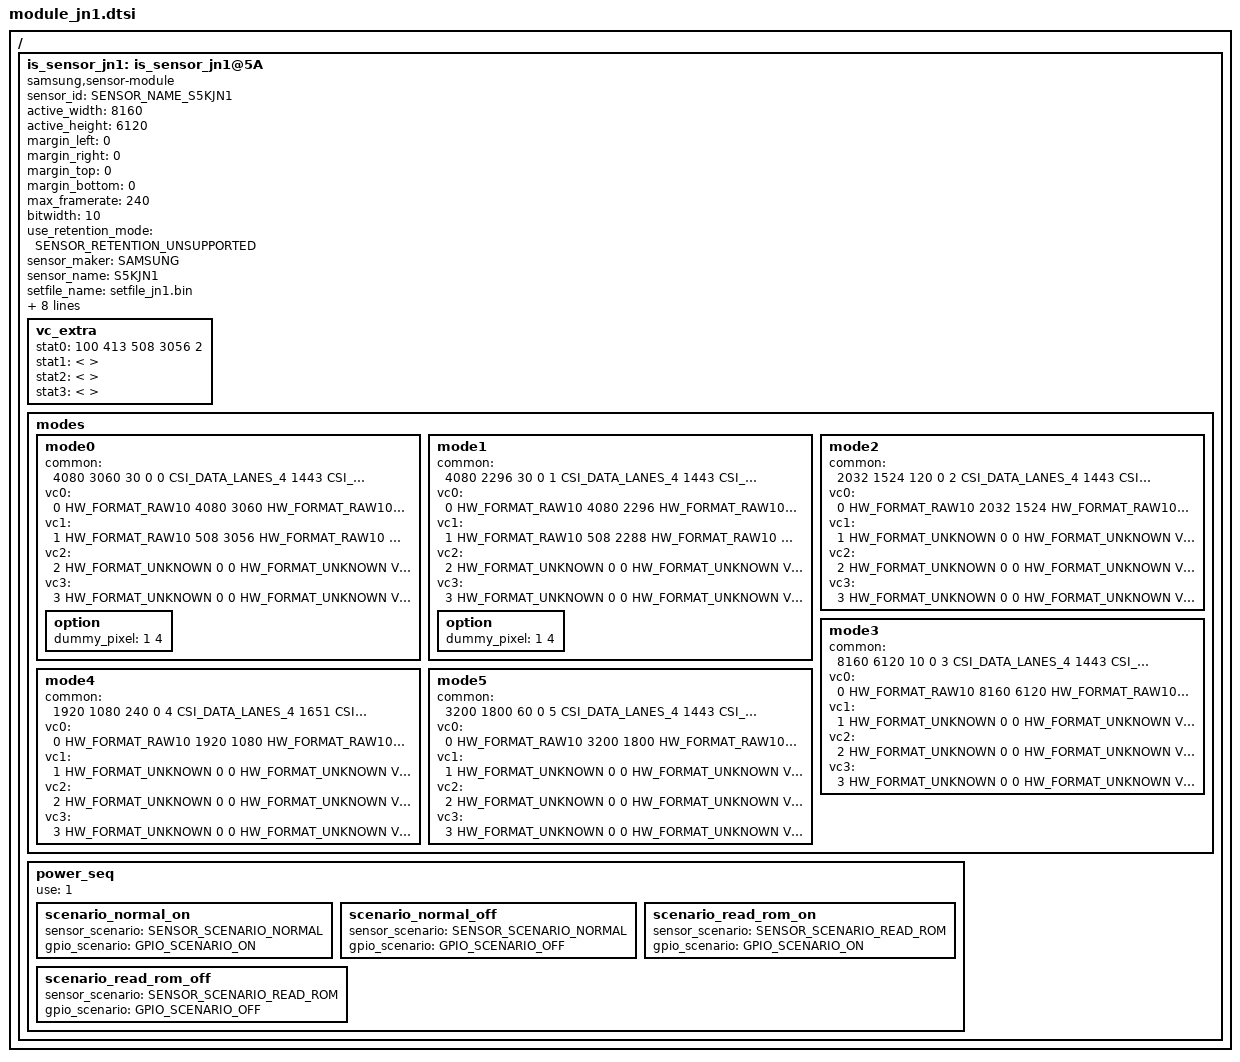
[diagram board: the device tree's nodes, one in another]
/*
 * SAMSUNG EXYNOSxxxx board camera device tree source
 *
 * Copyright (c) 2021 Samsung Electronics Co., Ltd.
 *		http://www.samsung.com
 *
 * This program is free software; you can redistribute it and/or modify
 * it under the terms of the GNU General Public License version 2 as
 * published by the Free Software Foundation.
 */

#include <dt-bindings/camera/exynos_is_dt.h>

#ifndef USE_VENDOR_PWR_PIN_NAME
#define RCAM_AF_VDD	<>
#define JN1_AVDD		<>
#define JN1_DVDD		<>
#define JN1_IOVDD	<>
#endif

/ {
	fragment@camera {
		target-path = "/";
		__overlay__ {
			is_sensor_jn1: is_sensor_jn1@5A {
				compatible = "samsung,sensor-module";

				/* common */
				sensor_id = <SENSOR_NAME_S5KJN1>;
				active_width = <8160>;
				active_height = <6120>;
				margin_left = <0>;
				margin_right = <0>;
				margin_top = <0>;
				margin_bottom = <0>;
				max_framerate = <240>;
				bitwidth = <10>;
				use_retention_mode = <SENSOR_RETENTION_UNSUPPORTED>;
				sensor_maker = "SAMSUNG";
				sensor_name = "S5KJN1";
				setfile_name = "setfile_jn1.bin";

				rcam_af_vdd-supply = RCAM_AF_VDD;
				jn1_avdd-supply = JN1_AVDD;
				jn1_dvdd-supply = JN1_DVDD;
				jn1_iovdd-supply = JN1_IOVDD;
				jn1_af-supply = RCAM_AF_VDD;

				status = "okay";

				/* vendor */
				rom_type = <2>; /* ROM_TYPE_EEPROM */
				rom_id = <0>;
				rom_cal_index = <0>;

				vc_extra {
					/* ex) statX = <stat_type, sensor_mode, max_width, max_height, max_element> */
					stat0 = </* VC_STAT_TYPE_TAIL_FOR_SW_PDAF */ 100 /* VC_SENSOR_MODE_SUPER_PD_5_TAIL */ 413 508 3056 2>; /* VC_BUF_DATA_TYPE_SENSOR_STAT1 */
					stat1 = </* not avaliable */>; /* VC_BUF_DATA_TYPE_GENERAL_STAT1 */
					stat2 = </* not avaliable */>; /* VC_BUF_DATA_TYPE_SENSOR_STAT2 */
					stat3 = </* not avaliable */>; /* VC_BUF_DATA_TYPE_GENERAL_STAT2 */
				};

				/* sensor modes */
				/* JN1 sensor setting version -  */
				/* 0: Remosaic mode A 4080x3060 30fps */

				modes {
						/* common = <width, height, fps, settle, mode, lane, speed, interleave, lrte, pd_mode> */
						/* vcX = <map, hwformat, width, height, hwformat, type, width, height> */
						mode0 {
							common = <4080 3060 30 0 0 CSI_DATA_LANES_4 1443 CSI_MODE_VC_ONLY LRTE_DISABLE PD_MSPD_TAIL EX_NONE>;
							vc0 = </* in */ 0 HW_FORMAT_RAW10 4080 3060    /* out */ HW_FORMAT_RAW10 VC_NOTHING 4080 3060>;
							vc1 = </* in */ 1 HW_FORMAT_RAW10 508 3056     /* out */ HW_FORMAT_RAW10 VC_TAILPDAF 508 3056>;
							vc2 = </* in */ 2 HW_FORMAT_UNKNOWN 0 0        /* out */ HW_FORMAT_UNKNOWN VC_NOTHING 0 0>;
							vc3 = </* in */ 3 HW_FORMAT_UNKNOWN 0 0        /* out */ HW_FORMAT_UNKNOWN VC_NOTHING 0 0>;
							option { dummy_pixel = <1 4>; }; /* HW constraint: for nacho, stat dma write should be performed with dummy pixel attached according to CSIS DMA align constraint */
						};
						mode1 {
							common = <4080 2296 30 0 1 CSI_DATA_LANES_4 1443 CSI_MODE_VC_ONLY LRTE_DISABLE PD_MSPD_TAIL EX_NONE>;
							vc0 = </* in */ 0 HW_FORMAT_RAW10 4080 2296    /* out */ HW_FORMAT_RAW10 VC_NOTHING 4080 2296>;
							vc1 = </* in */ 1 HW_FORMAT_RAW10 508 2288     /* out */ HW_FORMAT_RAW10 VC_TAILPDAF 508 2288>;
							vc2 = </* in */ 2 HW_FORMAT_UNKNOWN 0 0        /* out */ HW_FORMAT_UNKNOWN VC_NOTHING 0 0>;
							vc3 = </* in */ 3 HW_FORMAT_UNKNOWN 0 0        /* out */ HW_FORMAT_UNKNOWN VC_NOTHING 0 0>;
							option { dummy_pixel = <1 4>; }; /* HW constraint: for nacho, stat dma write should be performed with dummy pixel attached according to CSIS DMA align constraint */
						};
						mode2 {
							common = <2032 1524 120 0 2 CSI_DATA_LANES_4 1443 CSI_MODE_VC_ONLY LRTE_DISABLE PD_NONE EX_NONE>;
							vc0 = </* in */ 0 HW_FORMAT_RAW10 2032 1524    /* out */ HW_FORMAT_RAW10 VC_NOTHING 2032 1524>;
							vc1 = </* in */ 1 HW_FORMAT_UNKNOWN 0 0        /* out */ HW_FORMAT_UNKNOWN VC_NOTHING 0 0>;
							vc2 = </* in */ 2 HW_FORMAT_UNKNOWN 0 0        /* out */ HW_FORMAT_UNKNOWN VC_NOTHING 0 0>;
							vc3 = </* in */ 3 HW_FORMAT_UNKNOWN 0 0        /* out */ HW_FORMAT_UNKNOWN VC_NOTHING 0 0>;
						};
						mode3 {
							common = <8160 6120 10 0 3 CSI_DATA_LANES_4 1443 CSI_MODE_VC_ONLY LRTE_DISABLE PD_NONE EX_NONE>;
							vc0 = </* in */ 0 HW_FORMAT_RAW10 8160 6120    /* out */ HW_FORMAT_RAW10 VC_NOTHING 8160 6120>;
							vc1 = </* in */ 1 HW_FORMAT_UNKNOWN 0 0        /* out */ HW_FORMAT_UNKNOWN VC_NOTHING 0 0>;
							vc2 = </* in */ 2 HW_FORMAT_UNKNOWN 0 0        /* out */ HW_FORMAT_UNKNOWN VC_NOTHING 0 0>;
							vc3 = </* in */ 3 HW_FORMAT_UNKNOWN 0 0        /* out */ HW_FORMAT_UNKNOWN VC_NOTHING 0 0>;
						};
						mode4 {
							common = <1920 1080 240 0 4 CSI_DATA_LANES_4 1651 CSI_MODE_VC_ONLY LRTE_DISABLE PD_NONE EX_NONE>;
							vc0 = </* in */ 0 HW_FORMAT_RAW10 1920 1080    /* out */ HW_FORMAT_RAW10 VC_NOTHING 1920 1080>;
							vc1 = </* in */ 1 HW_FORMAT_UNKNOWN 0 0        /* out */ HW_FORMAT_UNKNOWN VC_NOTHING 0 0>;
							vc2 = </* in */ 2 HW_FORMAT_UNKNOWN 0 0        /* out */ HW_FORMAT_UNKNOWN VC_NOTHING 0 0>;
							vc3 = </* in */ 3 HW_FORMAT_UNKNOWN 0 0        /* out */ HW_FORMAT_UNKNOWN VC_NOTHING 0 0>;
						};
						mode5 {
							common = <3200 1800 60 0 5 CSI_DATA_LANES_4 1443 CSI_MODE_VC_ONLY LRTE_DISABLE PD_NONE EX_NONE>;
							vc0 = </* in */ 0 HW_FORMAT_RAW10 3200 1800    /* out */ HW_FORMAT_RAW10 VC_NOTHING 3200 1800>;
							vc1 = </* in */ 1 HW_FORMAT_UNKNOWN 0 0        /* out */ HW_FORMAT_UNKNOWN VC_NOTHING 0 0>;
							vc2 = </* in */ 2 HW_FORMAT_UNKNOWN 0 0        /* out */ HW_FORMAT_UNKNOWN VC_NOTHING 0 0>;
							vc3 = </* in */ 3 HW_FORMAT_UNKNOWN 0 0        /* out */ HW_FORMAT_UNKNOWN VC_NOTHING 0 0>;
						};
				};

				power_seq {
					use = <1>;
					scenario_normal_on {
						sensor_scenario = <SENSOR_SCENARIO_NORMAL>;
						gpio_scenario = <GPIO_SCENARIO_ON>;

						/* A start node number should be over the 10 for reserved number 0~9. */
						/* pname = "name"; pin = <act value dealy voltage>; gpio = <gpx# # 0x1>; */
					
					};

					scenario_normal_off {
						sensor_scenario = <SENSOR_SCENARIO_NORMAL>;
						gpio_scenario = <GPIO_SCENARIO_OFF>;

						/* A start node number should be over the 10 for reserved number 0~9. */
						/* pname = "name"; pin = <act value dealy voltage>; gpio = <gpx# # 0x1>; */
					};

					scenario_read_rom_on {
						sensor_scenario = <SENSOR_SCENARIO_READ_ROM>;
						gpio_scenario = <GPIO_SCENARIO_ON>;

						/* A start node number should be over the 10 for reserved number 0~9. */
						/* pname = "name"; pin = <act value dealy voltage>; gpio = <gpx# # 0x1>; */
					};

					scenario_read_rom_off {
						sensor_scenario = <SENSOR_SCENARIO_READ_ROM>;
						gpio_scenario = <GPIO_SCENARIO_OFF>;

						/* A start node number should be over the 10 for reserved number 0~9. */
						/* pname = "name"; pin = <act value dealy voltage>; gpio = <gpx# # 0x1>; */
					};
				};
			};
		}; /* end of __overlay__ */
	}; /* end of fragment */
}; /* end of root */
